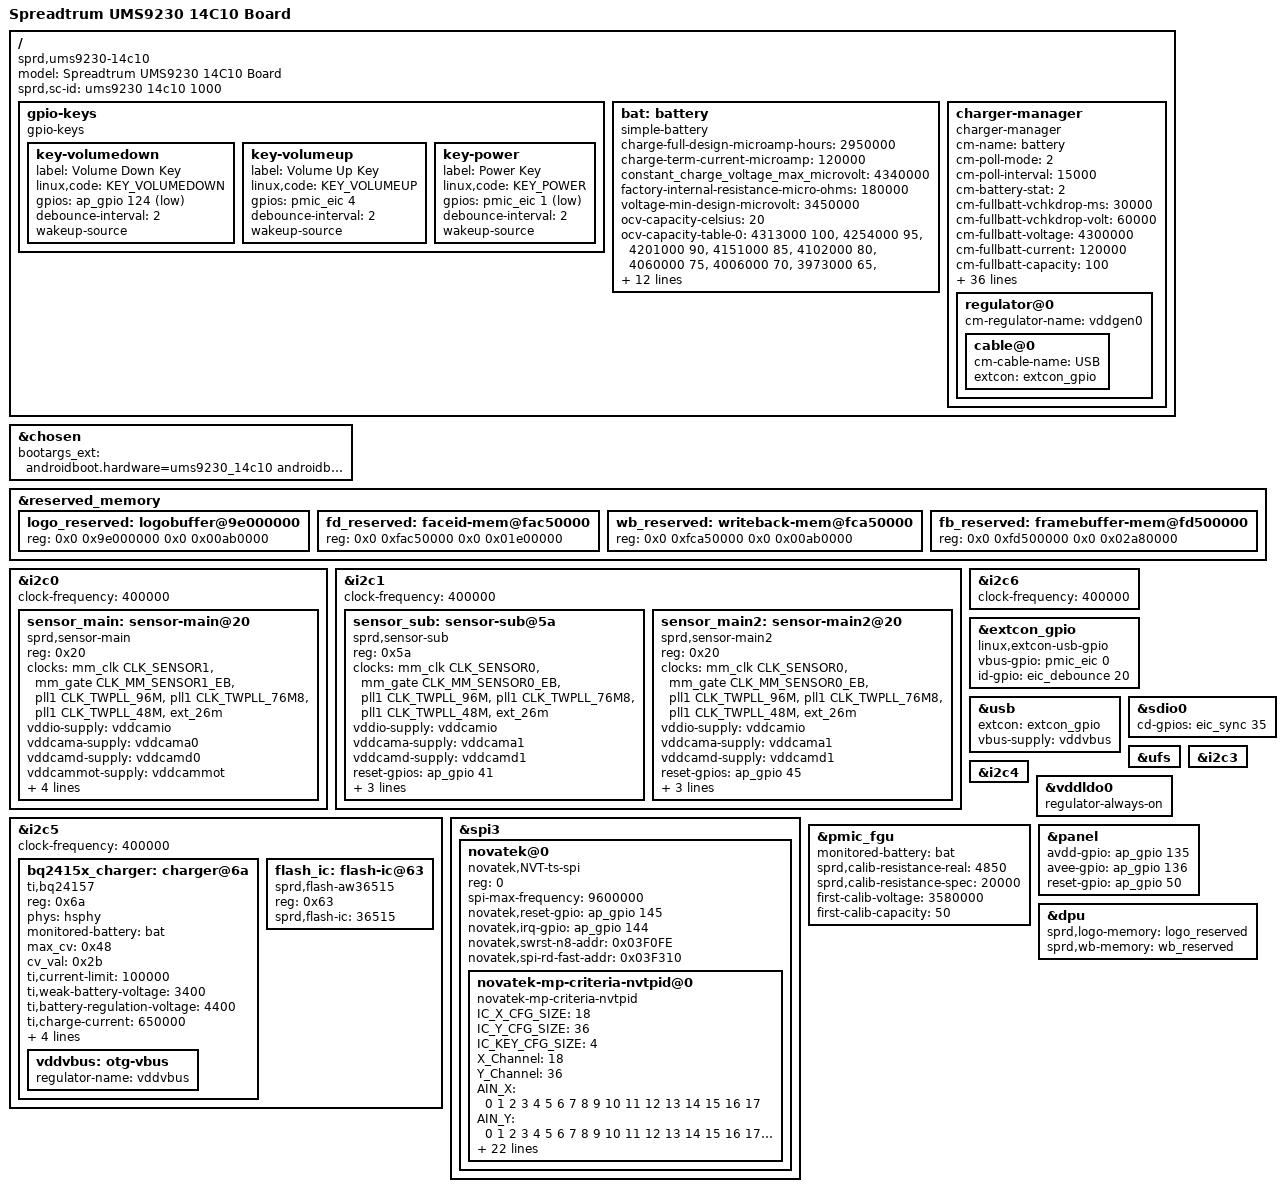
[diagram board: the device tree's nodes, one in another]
/dts-v1/;
/plugin/;
#include <dt-bindings/input/input.h>
#include <dt-bindings/gpio/gpio.h>
#include <dt-bindings/clock/sprd,ums9230-clk.h>
#include <dt-bindings/mfd/sprd,sc2730-regs.h>
#include <dt-bindings/mfd/sprd,sc2730-mask.h>
#include "lcd/lcd_nt36005b_mipi_hd.dtsi"

/ {

	model = "Spreadtrum UMS9230 14C10 Board";

	compatible = "sprd,ums9230-14c10";

	sprd,sc-id = "ums9230 14c10 1000";
	fragment {
		target-path = "/";
		__overlay__ {

			gpio-keys {
				compatible = "gpio-keys";

				key-volumedown {
					label = "Volume Down Key";
					linux,code = <KEY_VOLUMEDOWN>;
					gpios = <&ap_gpio 124 GPIO_ACTIVE_LOW>;
					debounce-interval = <2>;
					wakeup-source;
				};

				key-volumeup {
					label = "Volume Up Key";
					linux,code = <KEY_VOLUMEUP>;
					gpios = <&pmic_eic 4 GPIO_ACTIVE_HIGH>;
					debounce-interval = <2>;
					wakeup-source;
				};

				key-power {
					label = "Power Key";
					linux,code = <KEY_POWER>;
					gpios = <&pmic_eic 1 GPIO_ACTIVE_LOW>;
					debounce-interval = <2>;
					wakeup-source;
				};
			};

			bat: battery {
				compatible = "simple-battery";
				charge-full-design-microamp-hours = <2950000>;
				charge-term-current-microamp = <120000>;
				constant_charge_voltage_max_microvolt = <4340000>;
				factory-internal-resistance-micro-ohms = <180000>;
				voltage-min-design-microvolt = <3450000>;
				ocv-capacity-celsius = <20>;
				ocv-capacity-table-0 = <4313000 100>, <4254000 95>, <4201000 90>,
							<4151000 85>, <4102000 80>, <4060000 75>,
							<4006000 70>, <3973000 65>, <3930000 60>,
							<3882000 55>, <3851000 50>, <3829000 45>,
							<3810000 40>, <3795000 35>, <3781000 30>,
							<3765000 25>, <3746000 20>, <3722000 15>,
							<3694000 10>, <3682000 5>, <3400000 0>;
				capacity-temp-table = <45 100>, <25 100>, <10 98>, <0 93>, <(-10) 85>, <(-20) 64>;
				resistance-temp-table = <45 77>, <25 100>, <10 546>, <0 769>, <(-10) 892>, <(-20) 923>;
				charge-sdp-current-microamp = <500000 500000>;
				charge-dcp-current-microamp = <2000000 2000000>;
				charge-cdp-current-microamp = <1500000 1500000>;
				charge-unknown-current-microamp = <500000 500000>;
			};

			charger-manager {
				compatible = "charger-manager";
				cm-name = "battery";
				cm-poll-mode = <2>;
				cm-poll-interval = <15000>;
				cm-battery-stat = <2>;

				cm-fullbatt-vchkdrop-ms = <30000>;
				cm-fullbatt-vchkdrop-volt = <60000>;
				cm-fullbatt-voltage = <4300000>;
				cm-fullbatt-current = <120000>;
				cm-fullbatt-capacity = <100>;

				cm-num-chargers = <1>;
				cm-chargers = "bq24157";
				cm-fuel-gauge = "sc27xx-fgu";

				/* in deci centigrade */
				cm-battery-cold = <200>;
				cm-battery-cold-in-minus;
				cm-battery-hot = <800>;
				cm-battery-temp-diff = <100>;

				/* Allow charging for 6hr */
				cm-charging-max = <21600000>;
				/* recovery charging after stop charging 45min */
				cm-discharging-max = <2700000>;

				/* the interval to feed charger watchdog */
				cm-wdt-interval = <60>;

				/* drop voltage in microVolts to allow shutdown */
				cm-shutdown-voltage = <3100000>;

				/* when 99% of the time is exceeded, it will be forced to 100% */
				cm-tickle-time-out = <1500>;

				/* how much time to allow capacity change */
				cm-one-cap-time = <30>;
				/* cm-thermal-zone = "board-thmzone"; */
				/* when the safe charging voltage is exceeded, stop charging */
				cm-charge-voltage-max = <6500000>;
				/* drop voltage in microVolts to restart charging */
				cm-charge-voltage-drop = <700000>;
				cm-dcp-jeita-temp-table = <1000 1030 0 4400000>, <1150 1180 700000 4400000>,
					<1450 1420 2000000 4400000>, <1600 1570 700000 4100000>;
				cm-sdp-jeita-temp-table = <1000 1030 0 4400000>, <1150 1180 500000 4400000>,
					<1450 1420 500000 4400000>, <1600 1570 500000 4100000>;
				cm-cdp-jeita-temp-table = <1000 1030 0 4400000>, <1150 1180 700000 4400000>,
					<1450 1420 1500000 4400000>, <1600 1570 700000 4100000>;
				cm-unknown-jeita-temp-table = <1000 1030 0 4400000>, <1150 1180 500000 4400000>,
					<1450 1420 500000 4400000>, <1600 1570 500000 4100000>;

				monitored-battery = <&bat>;
				cm-capacity-track;

				cm-cap-remap-table = <1 2 3>, <2 3 2>, <98 99 2>, <99 100 3>;

				regulator@0 {
					cm-regulator-name = "vddgen0";
					cable@0 {
						cm-cable-name = "USB";
						extcon = <&extcon_gpio>;
					};
				};
			};
		};
	};
};

&chosen {
	bootargs_ext = "androidboot.hardware=ums9230_14c10 androidboot.dtbo_idx=0";
};

&reserved_memory {

	logo_reserved: logobuffer@9e000000{
		reg = <0x0 0x9e000000 0x0 0x00ab0000>;
	};

	fd_reserved: faceid-mem@fac50000 {
		reg = <0x0 0xfac50000 0x0 0x01e00000>;
	};

	wb_reserved: writeback-mem@fca50000 {
		reg = <0x0 0xfca50000 0x0 0x00ab0000>;
	};

	fb_reserved: framebuffer-mem@fd500000 {
		reg = <0x0 0xfd500000 0x0 0x02a80000>;
	};
};

&i2c0 {
	status = "okay";
	clock-frequency = <400000>;

	sensor_main: sensor-main@20 {
		compatible = "sprd,sensor-main";
		reg = <0x20>;
		clock-names = "clk_src","sensor_eb",
			"clk_96m","clk_76m8",
			"clk_48m","clk_26m";
		clocks = <&mm_clk CLK_SENSOR1>,<&mm_gate CLK_MM_SENSOR1_EB>,
				<&pll1 CLK_TWPLL_96M>,<&pll1 CLK_TWPLL_76M8>,
				<&pll1 CLK_TWPLL_48M>,<&ext_26m>;
		vddio-supply = <&vddcamio>;
		vddcama-supply = <&vddcama0>;
		vddcamd-supply = <&vddcamd0>;
		vddcammot-supply = <&vddcammot>;
		reset-gpios = <&ap_gpio 44 0>;
		power-down-gpios = <&ap_gpio 46 0>;
		sprd,phyid = <0>;
		csi = <&csi0>;
	};

};

&i2c1 {
	status = "okay";
	clock-frequency = <400000>;

	sensor_sub: sensor-sub@5a {
		compatible = "sprd,sensor-sub";
		reg = <0x5a>;
		clock-names = "clk_src","sensor_eb",
			"clk_96m","clk_76m8",
			"clk_48m","clk_26m";
		clocks = <&mm_clk CLK_SENSOR0>,<&mm_gate CLK_MM_SENSOR0_EB>,
				<&pll1 CLK_TWPLL_96M>,<&pll1 CLK_TWPLL_76M8>,
				<&pll1 CLK_TWPLL_48M>,<&ext_26m>;
		vddio-supply = <&vddcamio>;
		vddcama-supply = <&vddcama1>;
		vddcamd-supply = <&vddcamd1>;
		reset-gpios = <&ap_gpio 41 0>;
		power-down-gpios = <&ap_gpio 40 0>;
		sprd,phyid = <2>;
		csi = <&csi0>;
	};

	sensor_main2: sensor-main2@20 {
		compatible = "sprd,sensor-main2";
		reg = <0x20>;
		clock-names = "clk_src","sensor_eb",
			"clk_96m","clk_76m8",
			"clk_48m","clk_26m";
		clocks = <&mm_clk CLK_SENSOR0>,<&mm_gate CLK_MM_SENSOR0_EB>,
				<&pll1 CLK_TWPLL_96M>,<&pll1 CLK_TWPLL_76M8>,
				<&pll1 CLK_TWPLL_48M>,<&ext_26m>;
		vddio-supply = <&vddcamio>;
		vddcama-supply = <&vddcama1>;
		vddcamd-supply = <&vddcamd1>;
		reset-gpios = <&ap_gpio 45 0>;
		power-down-gpios = <&ap_gpio 47 0>;
		sprd,phyid = <4>;
		csi = <&csi1>;
	};
};

&i2c5 {
	status = "okay";
	clock-frequency = <400000>;

	bq2415x_charger: charger@6a {
		compatible = "ti,bq24157";
		reg = <0x6a>;
		phys = <&hsphy>;
		monitored-battery = <&bat>;
		max_cv = <0x48>;
		cv_val = <0x2b>;
		ti,current-limit = <100000>;
		ti,weak-battery-voltage = <3400>;
		ti,battery-regulation-voltage = <4400>;
		ti,charge-current = <650000>;
		ti,termination-current = <180000>;
		ti,resistor-sense = <56>;
		charge,chg-pd-gpio = <&ap_gpio 121 0>;
		extcon = <&extcon_gpio>;
		vddvbus:otg-vbus {
			regulator-name = "vddvbus";
		};
	};

	flash_ic: flash-ic@63 {
		compatible = "sprd,flash-aw36515";
		reg = <0x63>;
		sprd,flash-ic = <36515>;
	};
};

&i2c6 {
	status = "okay";
	clock-frequency = <400000>;
};

&spi3 {
	status = "ok";

	/* Novatek device tree node */
	novatek@0 {
		compatible = "novatek,NVT-ts-spi";
		reg = <0>; //Same as CS ID

		spi-max-frequency = <9600000>;	//4800000,9600000,15000000,19200000
		novatek,reset-gpio = <&ap_gpio 145 GPIO_ACTIVE_HIGH>;
		novatek,irq-gpio = <&ap_gpio 144 GPIO_ACTIVE_HIGH>;

		/* 525 */
		//novatek,swrst-n8-addr = <0x01F01A>;

		/* 672A, 525B, 675, 526, 672C */
		novatek,swrst-n8-addr = <0x03F0FE>;
		novatek,spi-rd-fast-addr = <0x03F310>;

		/* MP */
		//novatek,mp-support-dt;

		novatek-mp-criteria-nvtpid@0 {
			#address-cells = <1>;
			#size-cells = <0>;
			compatible = "novatek-mp-criteria-nvtpid";

			/* MP Config */
			IC_X_CFG_SIZE = <18>;
			IC_Y_CFG_SIZE = <36>;
			IC_KEY_CFG_SIZE = <4>;
			X_Channel = <18>;
			Y_Channel = <36>;
			AIN_X = <0 1 2 3 4 5 6 7 8 9 10 11 12 13 14 15 16 17>;
			AIN_Y = <0 1 2 3 4 5 6 7 8 9 10 11 12 13 14 15 16 17
						18 19 20 21 22 23 24 25 26 27 28 29 30 31 32 33 34 35>;
			AIN_KEY = <0 1 2 0xFF>;

			/* MP Criteria */
			PS_Config_Lmt_Short_Rawdata_P = <
				14008 14008 14008 14008 14008 14008 14008 14008 14008 14008 14008 14008 14008 14008 14008 14008 14008 14008
				14008 14008 14008 14008 14008 14008 14008 14008 14008 14008 14008 14008 14008 14008 14008 14008 14008 14008
				14008 14008 14008 14008 14008 14008 14008 14008 14008 14008 14008 14008 14008 14008 14008 14008 14008 14008
				14008 14008 14008 14008 14008 14008 14008 14008 14008 14008 14008 14008 14008 14008 14008 14008 14008 14008
				14008 14008 14008 14008 14008 14008 14008 14008 14008 14008 14008 14008 14008 14008 14008 14008 14008 14008
				14008 14008 14008 14008 14008 14008 14008 14008 14008 14008 14008 14008 14008 14008 14008 14008 14008 14008
				14008 14008 14008 14008 14008 14008 14008 14008 14008 14008 14008 14008 14008 14008 14008 14008 14008 14008
				14008 14008 14008 14008 14008 14008 14008 14008 14008 14008 14008 14008 14008 14008 14008 14008 14008 14008
				14008 14008 14008 14008 14008 14008 14008 14008 14008 14008 14008 14008 14008 14008 14008 14008 14008 14008
				14008 14008 14008 14008 14008 14008 14008 14008 14008 14008 14008 14008 14008 14008 14008 14008 14008 14008
				14008 14008 14008 14008 14008 14008 14008 14008 14008 14008 14008 14008 14008 14008 14008 14008 14008 14008
				14008 14008 14008 14008 14008 14008 14008 14008 14008 14008 14008 14008 14008 14008 14008 14008 14008 14008
				14008 14008 14008 14008 14008 14008 14008 14008 14008 14008 14008 14008 14008 14008 14008 14008 14008 14008
				14008 14008 14008 14008 14008 14008 14008 14008 14008 14008 14008 14008 14008 14008 14008 14008 14008 14008
				14008 14008 14008 14008 14008 14008 14008 14008 14008 14008 14008 14008 14008 14008 14008 14008 14008 14008
				14008 14008 14008 14008 14008 14008 14008 14008 14008 14008 14008 14008 14008 14008 14008 14008 14008 14008
				14008 14008 14008 14008 14008 14008 14008 14008 14008 14008 14008 14008 14008 14008 14008 14008 14008 14008
				14008 14008 14008 14008 14008 14008 14008 14008 14008 14008 14008 14008 14008 14008 14008 14008 14008 14008
				14008 14008 14008 14008 14008 14008 14008 14008 14008 14008 14008 14008 14008 14008 14008 14008 14008 14008
				14008 14008 14008 14008 14008 14008 14008 14008 14008 14008 14008 14008 14008 14008 14008 14008 14008 14008
				14008 14008 14008 14008 14008 14008 14008 14008 14008 14008 14008 14008 14008 14008 14008 14008 14008 14008
				14008 14008 14008 14008 14008 14008 14008 14008 14008 14008 14008 14008 14008 14008 14008 14008 14008 14008
				14008 14008 14008 14008 14008 14008 14008 14008 14008 14008 14008 14008 14008 14008 14008 14008 14008 14008
				14008 14008 14008 14008 14008 14008 14008 14008 14008 14008 14008 14008 14008 14008 14008 14008 14008 14008
				14008 14008 14008 14008 14008 14008 14008 14008 14008 14008 14008 14008 14008 14008 14008 14008 14008 14008
				14008 14008 14008 14008 14008 14008 14008 14008 14008 14008 14008 14008 14008 14008 14008 14008 14008 14008
				14008 14008 14008 14008 14008 14008 14008 14008 14008 14008 14008 14008 14008 14008 14008 14008 14008 14008
				14008 14008 14008 14008 14008 14008 14008 14008 14008 14008 14008 14008 14008 14008 14008 14008 14008 14008
				14008 14008 14008 14008 14008 14008 14008 14008 14008 14008 14008 14008 14008 14008 14008 14008 14008 14008
				14008 14008 14008 14008 14008 14008 14008 14008 14008 14008 14008 14008 14008 14008 14008 14008 14008 14008
				14008 14008 14008 14008 14008 14008 14008 14008 14008 14008 14008 14008 14008 14008 14008 14008 14008 14008
				14008 14008 14008 14008 14008 14008 14008 14008 14008 14008 14008 14008 14008 14008 14008 14008 14008 14008
				14008 14008 14008 14008 14008 14008 14008 14008 14008 14008 14008 14008 14008 14008 14008 14008 14008 14008
				14008 14008 14008 14008 14008 14008 14008 14008 14008 14008 14008 14008 14008 14008 14008 14008 14008 14008
				14008 14008 14008 14008 14008 14008 14008 14008 14008 14008 14008 14008 14008 14008 14008 14008 14008 14008
				14008 14008 14008 14008 14008 14008 14008 14008 14008 14008 14008 14008 14008 14008 14008 14008 14008 14008
				14008 14008 14008>;

			PS_Config_Lmt_Short_Rawdata_N = <
				10000 10000 10000 10000 10000 10000 10000 10000 10000 10000 10000 10000 10000 10000 10000 10000 10000 10000
				10000 10000 10000 10000 10000 10000 10000 10000 10000 10000 10000 10000 10000 10000 10000 10000 10000 10000
				10000 10000 10000 10000 10000 10000 10000 10000 10000 10000 10000 10000 10000 10000 10000 10000 10000 10000
				10000 10000 10000 10000 10000 10000 10000 10000 10000 10000 10000 10000 10000 10000 10000 10000 10000 10000
				10000 10000 10000 10000 10000 10000 10000 10000 10000 10000 10000 10000 10000 10000 10000 10000 10000 10000
				10000 10000 10000 10000 10000 10000 10000 10000 10000 10000 10000 10000 10000 10000 10000 10000 10000 10000
				10000 10000 10000 10000 10000 10000 10000 10000 10000 10000 10000 10000 10000 10000 10000 10000 10000 10000
				10000 10000 10000 10000 10000 10000 10000 10000 10000 10000 10000 10000 10000 10000 10000 10000 10000 10000
				10000 10000 10000 10000 10000 10000 10000 10000 10000 10000 10000 10000 10000 10000 10000 10000 10000 10000
				10000 10000 10000 10000 10000 10000 10000 10000 10000 10000 10000 10000 10000 10000 10000 10000 10000 10000
				10000 10000 10000 10000 10000 10000 10000 10000 10000 10000 10000 10000 10000 10000 10000 10000 10000 10000
				10000 10000 10000 10000 10000 10000 10000 10000 10000 10000 10000 10000 10000 10000 10000 10000 10000 10000
				10000 10000 10000 10000 10000 10000 10000 10000 10000 10000 10000 10000 10000 10000 10000 10000 10000 10000
				10000 10000 10000 10000 10000 10000 10000 10000 10000 10000 10000 10000 10000 10000 10000 10000 10000 10000
				10000 10000 10000 10000 10000 10000 10000 10000 10000 10000 10000 10000 10000 10000 10000 10000 10000 10000
				10000 10000 10000 10000 10000 10000 10000 10000 10000 10000 10000 10000 10000 10000 10000 10000 10000 10000
				10000 10000 10000 10000 10000 10000 10000 10000 10000 10000 10000 10000 10000 10000 10000 10000 10000 10000
				10000 10000 10000 10000 10000 10000 10000 10000 10000 10000 10000 10000 10000 10000 10000 10000 10000 10000
				10000 10000 10000 10000 10000 10000 10000 10000 10000 10000 10000 10000 10000 10000 10000 10000 10000 10000
				10000 10000 10000 10000 10000 10000 10000 10000 10000 10000 10000 10000 10000 10000 10000 10000 10000 10000
				10000 10000 10000 10000 10000 10000 10000 10000 10000 10000 10000 10000 10000 10000 10000 10000 10000 10000
				10000 10000 10000 10000 10000 10000 10000 10000 10000 10000 10000 10000 10000 10000 10000 10000 10000 10000
				10000 10000 10000 10000 10000 10000 10000 10000 10000 10000 10000 10000 10000 10000 10000 10000 10000 10000
				10000 10000 10000 10000 10000 10000 10000 10000 10000 10000 10000 10000 10000 10000 10000 10000 10000 10000
				10000 10000 10000 10000 10000 10000 10000 10000 10000 10000 10000 10000 10000 10000 10000 10000 10000 10000
				10000 10000 10000 10000 10000 10000 10000 10000 10000 10000 10000 10000 10000 10000 10000 10000 10000 10000
				10000 10000 10000 10000 10000 10000 10000 10000 10000 10000 10000 10000 10000 10000 10000 10000 10000 10000
				10000 10000 10000 10000 10000 10000 10000 10000 10000 10000 10000 10000 10000 10000 10000 10000 10000 10000
				10000 10000 10000 10000 10000 10000 10000 10000 10000 10000 10000 10000 10000 10000 10000 10000 10000 10000
				10000 10000 10000 10000 10000 10000 10000 10000 10000 10000 10000 10000 10000 10000 10000 10000 10000 10000
				10000 10000 10000 10000 10000 10000 10000 10000 10000 10000 10000 10000 10000 10000 10000 10000 10000 10000
				10000 10000 10000 10000 10000 10000 10000 10000 10000 10000 10000 10000 10000 10000 10000 10000 10000 10000
				10000 10000 10000 10000 10000 10000 10000 10000 10000 10000 10000 10000 10000 10000 10000 10000 10000 10000
				10000 10000 10000 10000 10000 10000 10000 10000 10000 10000 10000 10000 10000 10000 10000 10000 10000 10000
				10000 10000 10000 10000 10000 10000 10000 10000 10000 10000 10000 10000 10000 10000 10000 10000 10000 10000
				10000 10000 10000 10000 10000 10000 10000 10000 10000 10000 10000 10000 10000 10000 10000 10000 10000 10000
				10000 10000 10000>;

			PS_Config_Lmt_Open_Rawdata_P = <
				5120 5120 5120 5120 5120 5120 5120 5120 5120 5120 5120 5120 5120 5120 5120 5120 5120 5120
				5120 5120 5120 5120 5120 5120 5120 5120 5120 5120 5120 5120 5120 5120 5120 5120 5120 5120
				5120 5120 5120 5120 5120 5120 5120 5120 5120 5120 5120 5120 5120 5120 5120 5120 5120 5120
				5120 5120 5120 5120 5120 5120 5120 5120 5120 5120 5120 5120 5120 5120 5120 5120 5120 5120
				5120 5120 5120 5120 5120 5120 5120 5120 5120 5120 5120 5120 5120 5120 5120 5120 5120 5120
				5120 5120 5120 5120 5120 5120 5120 5120 5120 5120 5120 5120 5120 5120 5120 5120 5120 5120
				5120 5120 5120 5120 5120 5120 5120 5120 5120 5120 5120 5120 5120 5120 5120 5120 5120 5120
				5120 5120 5120 5120 5120 5120 5120 5120 5120 5120 5120 5120 5120 5120 5120 5120 5120 5120
				5120 5120 5120 5120 5120 5120 5120 5120 5120 5120 5120 5120 5120 5120 5120 5120 5120 5120
				5120 5120 5120 5120 5120 5120 5120 5120 5120 5120 5120 5120 5120 5120 5120 5120 5120 5120
				5120 5120 5120 5120 5120 5120 5120 5120 5120 5120 5120 5120 5120 5120 5120 5120 5120 5120
				5120 5120 5120 5120 5120 5120 5120 5120 5120 5120 5120 5120 5120 5120 5120 5120 5120 5120
				5120 5120 5120 5120 5120 5120 5120 5120 5120 5120 5120 5120 5120 5120 5120 5120 5120 5120
				5120 5120 5120 5120 5120 5120 5120 5120 5120 5120 5120 5120 5120 5120 5120 5120 5120 5120
				5120 5120 5120 5120 5120 5120 5120 5120 5120 5120 5120 5120 5120 5120 5120 5120 5120 5120
				5120 5120 5120 5120 5120 5120 5120 5120 5120 5120 5120 5120 5120 5120 5120 5120 5120 5120
				5120 5120 5120 5120 5120 5120 5120 5120 5120 5120 5120 5120 5120 5120 5120 5120 5120 5120
				5120 5120 5120 5120 5120 5120 5120 5120 5120 5120 5120 5120 5120 5120 5120 5120 5120 5120
				5120 5120 5120 5120 5120 5120 5120 5120 5120 5120 5120 5120 5120 5120 5120 5120 5120 5120
				5120 5120 5120 5120 5120 5120 5120 5120 5120 5120 5120 5120 5120 5120 5120 5120 5120 5120
				5120 5120 5120 5120 5120 5120 5120 5120 5120 5120 5120 5120 5120 5120 5120 5120 5120 5120
				5120 5120 5120 5120 5120 5120 5120 5120 5120 5120 5120 5120 5120 5120 5120 5120 5120 5120
				5120 5120 5120 5120 5120 5120 5120 5120 5120 5120 5120 5120 5120 5120 5120 5120 5120 5120
				5120 5120 5120 5120 5120 5120 5120 5120 5120 5120 5120 5120 5120 5120 5120 5120 5120 5120
				5120 5120 5120 5120 5120 5120 5120 5120 5120 5120 5120 5120 5120 5120 5120 5120 5120 5120
				5120 5120 5120 5120 5120 5120 5120 5120 5120 5120 5120 5120 5120 5120 5120 5120 5120 5120
				5120 5120 5120 5120 5120 5120 5120 5120 5120 5120 5120 5120 5120 5120 5120 5120 5120 5120
				5120 5120 5120 5120 5120 5120 5120 5120 5120 5120 5120 5120 5120 5120 5120 5120 5120 5120
				5120 5120 5120 5120 5120 5120 5120 5120 5120 5120 5120 5120 5120 5120 5120 5120 5120 5120
				5120 5120 5120 5120 5120 5120 5120 5120 5120 5120 5120 5120 5120 5120 5120 5120 5120 5120
				5120 5120 5120 5120 5120 5120 5120 5120 5120 5120 5120 5120 5120 5120 5120 5120 5120 5120
				5120 5120 5120 5120 5120 5120 5120 5120 5120 5120 5120 5120 5120 5120 5120 5120 5120 5120
				5120 5120 5120 5120 5120 5120 5120 5120 5120 5120 5120 5120 5120 5120 5120 5120 5120 5120
				5120 5120 5120 5120 5120 5120 5120 5120 5120 5120 5120 5120 5120 5120 5120 5120 5120 5120
				5120 5120 5120 5120 5120 5120 5120 5120 5120 5120 5120 5120 5120 5120 5120 5120 5120 5120
				5120 5120 5120 5120 5120 5120 5120 5120 5120 5120 5120 5120 5120 5120 5120 5120 5120 5120
				5120 5120 5120>;

			PS_Config_Lmt_Open_Rawdata_N = <
				(-511) (-511) (-511) (-511) (-511) (-511) (-511) (-511) (-511) (-511) (-511) (-511) (-511) (-511) (-511) (-511) (-511) (-511)
				(-511) (-511) (-511) (-511) (-511) (-511) (-511) (-511) (-511) (-511) (-511) (-511) (-511) (-511) (-511) (-511) (-511) (-511)
				(-511) (-511) (-511) (-511) (-511) (-511) (-511) (-511) (-511) (-511) (-511) (-511) (-511) (-511) (-511) (-511) (-511) (-511)
				(-511) (-511) (-511) (-511) (-511) (-511) (-511) (-511) (-511) (-511) (-511) (-511) (-511) (-511) (-511) (-511) (-511) (-511)
				(-511) (-511) (-511) (-511) (-511) (-511) (-511) (-511) (-511) (-511) (-511) (-511) (-511) (-511) (-511) (-511) (-511) (-511)
				(-511) (-511) (-511) (-511) (-511) (-511) (-511) (-511) (-511) (-511) (-511) (-511) (-511) (-511) (-511) (-511) (-511) (-511)
				(-511) (-511) (-511) (-511) (-511) (-511) (-511) (-511) (-511) (-511) (-511) (-511) (-511) (-511) (-511) (-511) (-511) (-511)
				(-511) (-511) (-511) (-511) (-511) (-511) (-511) (-511) (-511) (-511) (-511) (-511) (-511) (-511) (-511) (-511) (-511) (-511)
				(-511) (-511) (-511) (-511) (-511) (-511) (-511) (-511) (-511) (-511) (-511) (-511) (-511) (-511) (-511) (-511) (-511) (-511)
				(-511) (-511) (-511) (-511) (-511) (-511) (-511) (-511) (-511) (-511) (-511) (-511) (-511) (-511) (-511) (-511) (-511) (-511)
				(-511) (-511) (-511) (-511) (-511) (-511) (-511) (-511) (-511) (-511) (-511) (-511) (-511) (-511) (-511) (-511) (-511) (-511)
				(-511) (-511) (-511) (-511) (-511) (-511) (-511) (-511) (-511) (-511) (-511) (-511) (-511) (-511) (-511) (-511) (-511) (-511)
				(-511) (-511) (-511) (-511) (-511) (-511) (-511) (-511) (-511) (-511) (-511) (-511) (-511) (-511) (-511) (-511) (-511) (-511)
				(-511) (-511) (-511) (-511) (-511) (-511) (-511) (-511) (-511) (-511) (-511) (-511) (-511) (-511) (-511) (-511) (-511) (-511)
				(-511) (-511) (-511) (-511) (-511) (-511) (-511) (-511) (-511) (-511) (-511) (-511) (-511) (-511) (-511) (-511) (-511) (-511)
				(-511) (-511) (-511) (-511) (-511) (-511) (-511) (-511) (-511) (-511) (-511) (-511) (-511) (-511) (-511) (-511) (-511) (-511)
				(-511) (-511) (-511) (-511) (-511) (-511) (-511) (-511) (-511) (-511) (-511) (-511) (-511) (-511) (-511) (-511) (-511) (-511)
				(-511) (-511) (-511) (-511) (-511) (-511) (-511) (-511) (-511) (-511) (-511) (-511) (-511) (-511) (-511) (-511) (-511) (-511)
				(-511) (-511) (-511) (-511) (-511) (-511) (-511) (-511) (-511) (-511) (-511) (-511) (-511) (-511) (-511) (-511) (-511) (-511)
				(-511) (-511) (-511) (-511) (-511) (-511) (-511) (-511) (-511) (-511) (-511) (-511) (-511) (-511) (-511) (-511) (-511) (-511)
				(-511) (-511) (-511) (-511) (-511) (-511) (-511) (-511) (-511) (-511) (-511) (-511) (-511) (-511) (-511) (-511) (-511) (-511)
				(-511) (-511) (-511) (-511) (-511) (-511) (-511) (-511) (-511) (-511) (-511) (-511) (-511) (-511) (-511) (-511) (-511) (-511)
				(-511) (-511) (-511) (-511) (-511) (-511) (-511) (-511) (-511) (-511) (-511) (-511) (-511) (-511) (-511) (-511) (-511) (-511)
				(-511) (-511) (-511) (-511) (-511) (-511) (-511) (-511) (-511) (-511) (-511) (-511) (-511) (-511) (-511) (-511) (-511) (-511)
				(-511) (-511) (-511) (-511) (-511) (-511) (-511) (-511) (-511) (-511) (-511) (-511) (-511) (-511) (-511) (-511) (-511) (-511)
				(-511) (-511) (-511) (-511) (-511) (-511) (-511) (-511) (-511) (-511) (-511) (-511) (-511) (-511) (-511) (-511) (-511) (-511)
				(-511) (-511) (-511) (-511) (-511) (-511) (-511) (-511) (-511) (-511) (-511) (-511) (-511) (-511) (-511) (-511) (-511) (-511)
				(-511) (-511) (-511) (-511) (-511) (-511) (-511) (-511) (-511) (-511) (-511) (-511) (-511) (-511) (-511) (-511) (-511) (-511)
				(-511) (-511) (-511) (-511) (-511) (-511) (-511) (-511) (-511) (-511) (-511) (-511) (-511) (-511) (-511) (-511) (-511) (-511)
				(-511) (-511) (-511) (-511) (-511) (-511) (-511) (-511) (-511) (-511) (-511) (-511) (-511) (-511) (-511) (-511) (-511) (-511)
				(-511) (-511) (-511) (-511) (-511) (-511) (-511) (-511) (-511) (-511) (-511) (-511) (-511) (-511) (-511) (-511) (-511) (-511)
				(-511) (-511) (-511) (-511) (-511) (-511) (-511) (-511) (-511) (-511) (-511) (-511) (-511) (-511) (-511) (-511) (-511) (-511)
				(-511) (-511) (-511) (-511) (-511) (-511) (-511) (-511) (-511) (-511) (-511) (-511) (-511) (-511) (-511) (-511) (-511) (-511)
				(-511) (-511) (-511) (-511) (-511) (-511) (-511) (-511) (-511) (-511) (-511) (-511) (-511) (-511) (-511) (-511) (-511) (-511)
				(-511) (-511) (-511) (-511) (-511) (-511) (-511) (-511) (-511) (-511) (-511) (-511) (-511) (-511) (-511) (-511) (-511) (-511)
				(-511) (-511) (-511) (-511) (-511) (-511) (-511) (-511) (-511) (-511) (-511) (-511) (-511) (-511) (-511) (-511) (-511) (-511)
				(-511) (-511) (-511)>;

			PS_Config_Lmt_FW_Rawdata_P = <
				2560 2560 2560 2560 2560 2560 2560 2560 2560 2560 2560 2560 2560 2560 2560 2560 2560 2560
				2560 2560 2560 2560 2560 2560 2560 2560 2560 2560 2560 2560 2560 2560 2560 2560 2560 2560
				2560 2560 2560 2560 2560 2560 2560 2560 2560 2560 2560 2560 2560 2560 2560 2560 2560 2560
				2560 2560 2560 2560 2560 2560 2560 2560 2560 2560 2560 2560 2560 2560 2560 2560 2560 2560
				2560 2560 2560 2560 2560 2560 2560 2560 2560 2560 2560 2560 2560 2560 2560 2560 2560 2560
				2560 2560 2560 2560 2560 2560 2560 2560 2560 2560 2560 2560 2560 2560 2560 2560 2560 2560
				2560 2560 2560 2560 2560 2560 2560 2560 2560 2560 2560 2560 2560 2560 2560 2560 2560 2560
				2560 2560 2560 2560 2560 2560 2560 2560 2560 2560 2560 2560 2560 2560 2560 2560 2560 2560
				2560 2560 2560 2560 2560 2560 2560 2560 2560 2560 2560 2560 2560 2560 2560 2560 2560 2560
				2560 2560 2560 2560 2560 2560 2560 2560 2560 2560 2560 2560 2560 2560 2560 2560 2560 2560
				2560 2560 2560 2560 2560 2560 2560 2560 2560 2560 2560 2560 2560 2560 2560 2560 2560 2560
				2560 2560 2560 2560 2560 2560 2560 2560 2560 2560 2560 2560 2560 2560 2560 2560 2560 2560
				2560 2560 2560 2560 2560 2560 2560 2560 2560 2560 2560 2560 2560 2560 2560 2560 2560 2560
				2560 2560 2560 2560 2560 2560 2560 2560 2560 2560 2560 2560 2560 2560 2560 2560 2560 2560
				2560 2560 2560 2560 2560 2560 2560 2560 2560 2560 2560 2560 2560 2560 2560 2560 2560 2560
				2560 2560 2560 2560 2560 2560 2560 2560 2560 2560 2560 2560 2560 2560 2560 2560 2560 2560
				2560 2560 2560 2560 2560 2560 2560 2560 2560 2560 2560 2560 2560 2560 2560 2560 2560 2560
				2560 2560 2560 2560 2560 2560 2560 2560 2560 2560 2560 2560 2560 2560 2560 2560 2560 2560
				2560 2560 2560 2560 2560 2560 2560 2560 2560 2560 2560 2560 2560 2560 2560 2560 2560 2560
				2560 2560 2560 2560 2560 2560 2560 2560 2560 2560 2560 2560 2560 2560 2560 2560 2560 2560
				2560 2560 2560 2560 2560 2560 2560 2560 2560 2560 2560 2560 2560 2560 2560 2560 2560 2560
				2560 2560 2560 2560 2560 2560 2560 2560 2560 2560 2560 2560 2560 2560 2560 2560 2560 2560
				2560 2560 2560 2560 2560 2560 2560 2560 2560 2560 2560 2560 2560 2560 2560 2560 2560 2560
				2560 2560 2560 2560 2560 2560 2560 2560 2560 2560 2560 2560 2560 2560 2560 2560 2560 2560
				2560 2560 2560 2560 2560 2560 2560 2560 2560 2560 2560 2560 2560 2560 2560 2560 2560 2560
				2560 2560 2560 2560 2560 2560 2560 2560 2560 2560 2560 2560 2560 2560 2560 2560 2560 2560
				2560 2560 2560 2560 2560 2560 2560 2560 2560 2560 2560 2560 2560 2560 2560 2560 2560 2560
				2560 2560 2560 2560 2560 2560 2560 2560 2560 2560 2560 2560 2560 2560 2560 2560 2560 2560
				2560 2560 2560 2560 2560 2560 2560 2560 2560 2560 2560 2560 2560 2560 2560 2560 2560 2560
				2560 2560 2560 2560 2560 2560 2560 2560 2560 2560 2560 2560 2560 2560 2560 2560 2560 2560
				2560 2560 2560 2560 2560 2560 2560 2560 2560 2560 2560 2560 2560 2560 2560 2560 2560 2560
				2560 2560 2560 2560 2560 2560 2560 2560 2560 2560 2560 2560 2560 2560 2560 2560 2560 2560
				2560 2560 2560 2560 2560 2560 2560 2560 2560 2560 2560 2560 2560 2560 2560 2560 2560 2560
				2560 2560 2560 2560 2560 2560 2560 2560 2560 2560 2560 2560 2560 2560 2560 2560 2560 2560
				2560 2560 2560 2560 2560 2560 2560 2560 2560 2560 2560 2560 2560 2560 2560 2560 2560 2560
				2560 2560 2560 2560 2560 2560 2560 2560 2560 2560 2560 2560 2560 2560 2560 2560 2560 2560
				2560 2560 2560>;

			PS_Config_Lmt_FW_Rawdata_N = <
				240 240 240 240 240 240 240 240 240 240 240 240 240 240 240 240 240 240
				240 240 240 240 240 240 240 240 240 240 240 240 240 240 240 240 240 240
				240 240 240 240 240 240 240 240 240 240 240 240 240 240 240 240 240 240
				240 240 240 240 240 240 240 240 240 240 240 240 240 240 240 240 240 240
				240 240 240 240 240 240 240 240 240 240 240 240 240 240 240 240 240 240
				240 240 240 240 240 240 240 240 240 240 240 240 240 240 240 240 240 240
				240 240 240 240 240 240 240 240 240 240 240 240 240 240 240 240 240 240
				240 240 240 240 240 240 240 240 240 240 240 240 240 240 240 240 240 240
				240 240 240 240 240 240 240 240 240 240 240 240 240 240 240 240 240 240
				240 240 240 240 240 240 240 240 240 240 240 240 240 240 240 240 240 240
				240 240 240 240 240 240 240 240 240 240 240 240 240 240 240 240 240 240
				240 240 240 240 240 240 240 240 240 240 240 240 240 240 240 240 240 240
				240 240 240 240 240 240 240 240 240 240 240 240 240 240 240 240 240 240
				240 240 240 240 240 240 240 240 240 240 240 240 240 240 240 240 240 240
				240 240 240 240 240 240 240 240 240 240 240 240 240 240 240 240 240 240
				240 240 240 240 240 240 240 240 240 240 240 240 240 240 240 240 240 240
				240 240 240 240 240 240 240 240 240 240 240 240 240 240 240 240 240 240
				240 240 240 240 240 240 240 240 240 240 240 240 240 240 240 240 240 240
				240 240 240 240 240 240 240 240 240 240 240 240 240 240 240 240 240 240
				240 240 240 240 240 240 240 240 240 240 240 240 240 240 240 240 240 240
				240 240 240 240 240 240 240 240 240 240 240 240 240 240 240 240 240 240
				240 240 240 240 240 240 240 240 240 240 240 240 240 240 240 240 240 240
				240 240 240 240 240 240 240 240 240 240 240 240 240 240 240 240 240 240
				240 240 240 240 240 240 240 240 240 240 240 240 240 240 240 240 240 240
				240 240 240 240 240 240 240 240 240 240 240 240 240 240 240 240 240 240
				240 240 240 240 240 240 240 240 240 240 240 240 240 240 240 240 240 240
				240 240 240 240 240 240 240 240 240 240 240 240 240 240 240 240 240 240
				240 240 240 240 240 240 240 240 240 240 240 240 240 240 240 240 240 240
				240 240 240 240 240 240 240 240 240 240 240 240 240 240 240 240 240 240
				240 240 240 240 240 240 240 240 240 240 240 240 240 240 240 240 240 240
				240 240 240 240 240 240 240 240 240 240 240 240 240 240 240 240 240 240
				240 240 240 240 240 240 240 240 240 240 240 240 240 240 240 240 240 240
				240 240 240 240 240 240 240 240 240 240 240 240 240 240 240 240 240 240
				240 240 240 240 240 240 240 240 240 240 240 240 240 240 240 240 240 240
				240 240 240 240 240 240 240 240 240 240 240 240 240 240 240 240 240 240
				240 240 240 240 240 240 240 240 240 240 240 240 240 240 240 240 240 240
				240 240 240>;

			PS_Config_Lmt_FW_CC_P = <
				314 314 314 314 314 314 314 314 314 314 314 314 314 314 314 314 314 314
				314 314 314 314 314 314 314 314 314 314 314 314 314 314 314 314 314 314
				314 314 314 314 314 314 314 314 314 314 314 314 314 314 314 314 314 314
				314 314 314 314 314 314 314 314 314 314 314 314 314 314 314 314 314 314
				314 314 314 314 314 314 314 314 314 314 314 314 314 314 314 314 314 314
				314 314 314 314 314 314 314 314 314 314 314 314 314 314 314 314 314 314
				314 314 314 314 314 314 314 314 314 314 314 314 314 314 314 314 314 314
				314 314 314 314 314 314 314 314 314 314 314 314 314 314 314 314 314 314
				314 314 314 314 314 314 314 314 314 314 314 314 314 314 314 314 314 314
				314 314 314 314 314 314 314 314 314 314 314 314 314 314 314 314 314 314
				314 314 314 314 314 314 314 314 314 314 314 314 314 314 314 314 314 314
				314 314 314 314 314 314 314 314 314 314 314 314 314 314 314 314 314 314
				314 314 314 314 314 314 314 314 314 314 314 314 314 314 314 314 314 314
				314 314 314 314 314 314 314 314 314 314 314 314 314 314 314 314 314 314
				314 314 314 314 314 314 314 314 314 314 314 314 314 314 314 314 314 314
				314 314 314 314 314 314 314 314 314 314 314 314 314 314 314 314 314 314
				314 314 314 314 314 314 314 314 314 314 314 314 314 314 314 314 314 314
				314 314 314 314 314 314 314 314 314 314 314 314 314 314 314 314 314 314
				314 314 314 314 314 314 314 314 314 314 314 314 314 314 314 314 314 314
				314 314 314 314 314 314 314 314 314 314 314 314 314 314 314 314 314 314
				314 314 314 314 314 314 314 314 314 314 314 314 314 314 314 314 314 314
				314 314 314 314 314 314 314 314 314 314 314 314 314 314 314 314 314 314
				314 314 314 314 314 314 314 314 314 314 314 314 314 314 314 314 314 314
				314 314 314 314 314 314 314 314 314 314 314 314 314 314 314 314 314 314
				314 314 314 314 314 314 314 314 314 314 314 314 314 314 314 314 314 314
				314 314 314 314 314 314 314 314 314 314 314 314 314 314 314 314 314 314
				314 314 314 314 314 314 314 314 314 314 314 314 314 314 314 314 314 314
				314 314 314 314 314 314 314 314 314 314 314 314 314 314 314 314 314 314
				314 314 314 314 314 314 314 314 314 314 314 314 314 314 314 314 314 314
				314 314 314 314 314 314 314 314 314 314 314 314 314 314 314 314 314 314
				314 314 314 314 314 314 314 314 314 314 314 314 314 314 314 314 314 314
				314 314 314 314 314 314 314 314 314 314 314 314 314 314 314 314 314 314
				314 314 314 314 314 314 314 314 314 314 314 314 314 314 314 314 314 314
				314 314 314 314 314 314 314 314 314 314 314 314 314 314 314 314 314 314
				314 314 314 314 314 314 314 314 314 314 314 314 314 314 314 314 314 314
				314 314 314 314 314 314 314 314 314 314 314 314 314 314 314 314 314 314
				314 314 314>;

			PS_Config_Lmt_FW_CC_N = <
				0 0 0 0 0 0 0 0 0 0 0 0 0 0 0 0 0 0
				0 0 0 0 0 0 0 0 0 0 0 0 0 0 0 0 0 0
				0 0 0 0 0 0 0 0 0 0 0 0 0 0 0 0 0 0
				0 0 0 0 0 0 0 0 0 0 0 0 0 0 0 0 0 0
				0 0 0 0 0 0 0 0 0 0 0 0 0 0 0 0 0 0
				0 0 0 0 0 0 0 0 0 0 0 0 0 0 0 0 0 0
				0 0 0 0 0 0 0 0 0 0 0 0 0 0 0 0 0 0
				0 0 0 0 0 0 0 0 0 0 0 0 0 0 0 0 0 0
				0 0 0 0 0 0 0 0 0 0 0 0 0 0 0 0 0 0
				0 0 0 0 0 0 0 0 0 0 0 0 0 0 0 0 0 0
				0 0 0 0 0 0 0 0 0 0 0 0 0 0 0 0 0 0
				0 0 0 0 0 0 0 0 0 0 0 0 0 0 0 0 0 0
				0 0 0 0 0 0 0 0 0 0 0 0 0 0 0 0 0 0
				0 0 0 0 0 0 0 0 0 0 0 0 0 0 0 0 0 0
				0 0 0 0 0 0 0 0 0 0 0 0 0 0 0 0 0 0
				0 0 0 0 0 0 0 0 0 0 0 0 0 0 0 0 0 0
				0 0 0 0 0 0 0 0 0 0 0 0 0 0 0 0 0 0
				0 0 0 0 0 0 0 0 0 0 0 0 0 0 0 0 0 0
				0 0 0 0 0 0 0 0 0 0 0 0 0 0 0 0 0 0
				0 0 0 0 0 0 0 0 0 0 0 0 0 0 0 0 0 0
				0 0 0 0 0 0 0 0 0 0 0 0 0 0 0 0 0 0
				0 0 0 0 0 0 0 0 0 0 0 0 0 0 0 0 0 0
				0 0 0 0 0 0 0 0 0 0 0 0 0 0 0 0 0 0
				0 0 0 0 0 0 0 0 0 0 0 0 0 0 0 0 0 0
				0 0 0 0 0 0 0 0 0 0 0 0 0 0 0 0 0 0
				0 0 0 0 0 0 0 0 0 0 0 0 0 0 0 0 0 0
				0 0 0 0 0 0 0 0 0 0 0 0 0 0 0 0 0 0
				0 0 0 0 0 0 0 0 0 0 0 0 0 0 0 0 0 0
				0 0 0 0 0 0 0 0 0 0 0 0 0 0 0 0 0 0
				0 0 0 0 0 0 0 0 0 0 0 0 0 0 0 0 0 0
				0 0 0 0 0 0 0 0 0 0 0 0 0 0 0 0 0 0
				0 0 0 0 0 0 0 0 0 0 0 0 0 0 0 0 0 0
				0 0 0 0 0 0 0 0 0 0 0 0 0 0 0 0 0 0
				0 0 0 0 0 0 0 0 0 0 0 0 0 0 0 0 0 0
				0 0 0 0 0 0 0 0 0 0 0 0 0 0 0 0 0 0
				0 0 0 0 0 0 0 0 0 0 0 0 0 0 0 0 0 0
				0 0 0>;

			PS_Config_Lmt_FW_Diff_P = <
				75 75 75 75 75 75 75 75 75 75 75 75 75 75 75 75 75 75
				75 75 75 75 75 75 75 75 75 75 75 75 75 75 75 75 75 75
				75 75 75 75 75 75 75 75 75 75 75 75 75 75 75 75 75 75
				75 75 75 75 75 75 75 75 75 75 75 75 75 75 75 75 75 75
				75 75 75 75 75 75 75 75 75 75 75 75 75 75 75 75 75 75
				75 75 75 75 75 75 75 75 75 75 75 75 75 75 75 75 75 75
				75 75 75 75 75 75 75 75 75 75 75 75 75 75 75 75 75 75
				75 75 75 75 75 75 75 75 75 75 75 75 75 75 75 75 75 75
				75 75 75 75 75 75 75 75 75 75 75 75 75 75 75 75 75 75
				75 75 75 75 75 75 75 75 75 75 75 75 75 75 75 75 75 75
				75 75 75 75 75 75 75 75 75 75 75 75 75 75 75 75 75 75
				75 75 75 75 75 75 75 75 75 75 75 75 75 75 75 75 75 75
				75 75 75 75 75 75 75 75 75 75 75 75 75 75 75 75 75 75
				75 75 75 75 75 75 75 75 75 75 75 75 75 75 75 75 75 75
				75 75 75 75 75 75 75 75 75 75 75 75 75 75 75 75 75 75
				75 75 75 75 75 75 75 75 75 75 75 75 75 75 75 75 75 75
				75 75 75 75 75 75 75 75 75 75 75 75 75 75 75 75 75 75
				75 75 75 75 75 75 75 75 75 75 75 75 75 75 75 75 75 75
				75 75 75 75 75 75 75 75 75 75 75 75 75 75 75 75 75 75
				75 75 75 75 75 75 75 75 75 75 75 75 75 75 75 75 75 75
				75 75 75 75 75 75 75 75 75 75 75 75 75 75 75 75 75 75
				75 75 75 75 75 75 75 75 75 75 75 75 75 75 75 75 75 75
				75 75 75 75 75 75 75 75 75 75 75 75 75 75 75 75 75 75
				75 75 75 75 75 75 75 75 75 75 75 75 75 75 75 75 75 75
				75 75 75 75 75 75 75 75 75 75 75 75 75 75 75 75 75 75
				75 75 75 75 75 75 75 75 75 75 75 75 75 75 75 75 75 75
				75 75 75 75 75 75 75 75 75 75 75 75 75 75 75 75 75 75
				75 75 75 75 75 75 75 75 75 75 75 75 75 75 75 75 75 75
				75 75 75 75 75 75 75 75 75 75 75 75 75 75 75 75 75 75
				75 75 75 75 75 75 75 75 75 75 75 75 75 75 75 75 75 75
				75 75 75 75 75 75 75 75 75 75 75 75 75 75 75 75 75 75
				75 75 75 75 75 75 75 75 75 75 75 75 75 75 75 75 75 75
				75 75 75 75 75 75 75 75 75 75 75 75 75 75 75 75 75 75
				75 75 75 75 75 75 75 75 75 75 75 75 75 75 75 75 75 75
				75 75 75 75 75 75 75 75 75 75 75 75 75 75 75 75 75 75
				75 75 75 75 75 75 75 75 75 75 75 75 75 75 75 75 75 75
				75 75 75>;

			PS_Config_Lmt_FW_Diff_N = <
				(-75) (-75) (-75) (-75) (-75) (-75) (-75) (-75) (-75) (-75) (-75) (-75) (-75) (-75) (-75) (-75) (-75) (-75)
				(-75) (-75) (-75) (-75) (-75) (-75) (-75) (-75) (-75) (-75) (-75) (-75) (-75) (-75) (-75) (-75) (-75) (-75)
				(-75) (-75) (-75) (-75) (-75) (-75) (-75) (-75) (-75) (-75) (-75) (-75) (-75) (-75) (-75) (-75) (-75) (-75)
				(-75) (-75) (-75) (-75) (-75) (-75) (-75) (-75) (-75) (-75) (-75) (-75) (-75) (-75) (-75) (-75) (-75) (-75)
				(-75) (-75) (-75) (-75) (-75) (-75) (-75) (-75) (-75) (-75) (-75) (-75) (-75) (-75) (-75) (-75) (-75) (-75)
				(-75) (-75) (-75) (-75) (-75) (-75) (-75) (-75) (-75) (-75) (-75) (-75) (-75) (-75) (-75) (-75) (-75) (-75)
				(-75) (-75) (-75) (-75) (-75) (-75) (-75) (-75) (-75) (-75) (-75) (-75) (-75) (-75) (-75) (-75) (-75) (-75)
				(-75) (-75) (-75) (-75) (-75) (-75) (-75) (-75) (-75) (-75) (-75) (-75) (-75) (-75) (-75) (-75) (-75) (-75)
				(-75) (-75) (-75) (-75) (-75) (-75) (-75) (-75) (-75) (-75) (-75) (-75) (-75) (-75) (-75) (-75) (-75) (-75)
				(-75) (-75) (-75) (-75) (-75) (-75) (-75) (-75) (-75) (-75) (-75) (-75) (-75) (-75) (-75) (-75) (-75) (-75)
				(-75) (-75) (-75) (-75) (-75) (-75) (-75) (-75) (-75) (-75) (-75) (-75) (-75) (-75) (-75) (-75) (-75) (-75)
				(-75) (-75) (-75) (-75) (-75) (-75) (-75) (-75) (-75) (-75) (-75) (-75) (-75) (-75) (-75) (-75) (-75) (-75)
				(-75) (-75) (-75) (-75) (-75) (-75) (-75) (-75) (-75) (-75) (-75) (-75) (-75) (-75) (-75) (-75) (-75) (-75)
				(-75) (-75) (-75) (-75) (-75) (-75) (-75) (-75) (-75) (-75) (-75) (-75) (-75) (-75) (-75) (-75) (-75) (-75)
				(-75) (-75) (-75) (-75) (-75) (-75) (-75) (-75) (-75) (-75) (-75) (-75) (-75) (-75) (-75) (-75) (-75) (-75)
				(-75) (-75) (-75) (-75) (-75) (-75) (-75) (-75) (-75) (-75) (-75) (-75) (-75) (-75) (-75) (-75) (-75) (-75)
				(-75) (-75) (-75) (-75) (-75) (-75) (-75) (-75) (-75) (-75) (-75) (-75) (-75) (-75) (-75) (-75) (-75) (-75)
				(-75) (-75) (-75) (-75) (-75) (-75) (-75) (-75) (-75) (-75) (-75) (-75) (-75) (-75) (-75) (-75) (-75) (-75)
				(-75) (-75) (-75) (-75) (-75) (-75) (-75) (-75) (-75) (-75) (-75) (-75) (-75) (-75) (-75) (-75) (-75) (-75)
				(-75) (-75) (-75) (-75) (-75) (-75) (-75) (-75) (-75) (-75) (-75) (-75) (-75) (-75) (-75) (-75) (-75) (-75)
				(-75) (-75) (-75) (-75) (-75) (-75) (-75) (-75) (-75) (-75) (-75) (-75) (-75) (-75) (-75) (-75) (-75) (-75)
				(-75) (-75) (-75) (-75) (-75) (-75) (-75) (-75) (-75) (-75) (-75) (-75) (-75) (-75) (-75) (-75) (-75) (-75)
				(-75) (-75) (-75) (-75) (-75) (-75) (-75) (-75) (-75) (-75) (-75) (-75) (-75) (-75) (-75) (-75) (-75) (-75)
				(-75) (-75) (-75) (-75) (-75) (-75) (-75) (-75) (-75) (-75) (-75) (-75) (-75) (-75) (-75) (-75) (-75) (-75)
				(-75) (-75) (-75) (-75) (-75) (-75) (-75) (-75) (-75) (-75) (-75) (-75) (-75) (-75) (-75) (-75) (-75) (-75)
				(-75) (-75) (-75) (-75) (-75) (-75) (-75) (-75) (-75) (-75) (-75) (-75) (-75) (-75) (-75) (-75) (-75) (-75)
				(-75) (-75) (-75) (-75) (-75) (-75) (-75) (-75) (-75) (-75) (-75) (-75) (-75) (-75) (-75) (-75) (-75) (-75)
				(-75) (-75) (-75) (-75) (-75) (-75) (-75) (-75) (-75) (-75) (-75) (-75) (-75) (-75) (-75) (-75) (-75) (-75)
				(-75) (-75) (-75) (-75) (-75) (-75) (-75) (-75) (-75) (-75) (-75) (-75) (-75) (-75) (-75) (-75) (-75) (-75)
				(-75) (-75) (-75) (-75) (-75) (-75) (-75) (-75) (-75) (-75) (-75) (-75) (-75) (-75) (-75) (-75) (-75) (-75)
				(-75) (-75) (-75) (-75) (-75) (-75) (-75) (-75) (-75) (-75) (-75) (-75) (-75) (-75) (-75) (-75) (-75) (-75)
				(-75) (-75) (-75) (-75) (-75) (-75) (-75) (-75) (-75) (-75) (-75) (-75) (-75) (-75) (-75) (-75) (-75) (-75)
				(-75) (-75) (-75) (-75) (-75) (-75) (-75) (-75) (-75) (-75) (-75) (-75) (-75) (-75) (-75) (-75) (-75) (-75)
				(-75) (-75) (-75) (-75) (-75) (-75) (-75) (-75) (-75) (-75) (-75) (-75) (-75) (-75) (-75) (-75) (-75) (-75)
				(-75) (-75) (-75) (-75) (-75) (-75) (-75) (-75) (-75) (-75) (-75) (-75) (-75) (-75) (-75) (-75) (-75) (-75)
				(-75) (-75) (-75) (-75) (-75) (-75) (-75) (-75) (-75) (-75) (-75) (-75) (-75) (-75) (-75) (-75) (-75) (-75)
				(-75) (-75) (-75)>;

			PS_Config_Diff_Test_Frame = <50>;
		};
	};
};

&extcon_gpio {
	compatible = "linux,extcon-usb-gpio";
	vbus-gpio = <&pmic_eic 0 GPIO_ACTIVE_HIGH>;
	id-gpio = <&eic_debounce 20 GPIO_ACTIVE_HIGH>;
};

&usb {
	extcon = <&extcon_gpio>;
	vbus-supply = <&vddvbus>;
};

&sdio0 {
	cd-gpios = <&eic_sync 35 GPIO_ACTIVE_HIGH>;
};

&ufs {
	status = "okay";
};

&i2c3 {
	status = "okay";
};

&i2c4 {
	status = "okay";
};


&vddldo0 {
	regulator-always-on;
};

&pmic_fgu {
	monitored-battery = <&bat>;
	sprd,calib-resistance-real = <4850>;
	sprd,calib-resistance-spec = <20000>;
	first-calib-voltage = <3580000>;
	first-calib-capacity = <50>;
};

&panel {
	avdd-gpio = <&ap_gpio 135 GPIO_ACTIVE_HIGH>;
	avee-gpio = <&ap_gpio 136 GPIO_ACTIVE_HIGH>;
	reset-gpio = <&ap_gpio 50 GPIO_ACTIVE_HIGH>;
};

&dpu {
	sprd,logo-memory = <&logo_reserved>;
	sprd,wb-memory = <&wb_reserved>;
};
